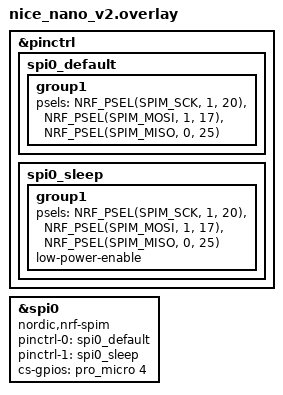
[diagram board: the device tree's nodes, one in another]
/*
 * Copyright (c) 2024 Curtis Bollinger
 *
 * SPDX-License-Identifier: MIT
 */

&pinctrl {
    spi0_default: spi0_default {
        group1 {
            psels = <NRF_PSEL(SPIM_SCK, 1, 20)>,  //SCL P3
                    <NRF_PSEL(SPIM_MOSI, 1, 17)>, //SDA P2
                    <NRF_PSEL(SPIM_MISO, 0, 25)>;
        };
    };
    spi0_sleep: spi0_sleep {
        group1 {
            psels = <NRF_PSEL(SPIM_SCK, 1, 20)>,
                    <NRF_PSEL(SPIM_MOSI, 1, 17)>,
                    <NRF_PSEL(SPIM_MISO, 0, 25)>;
            low-power-enable;
        };
    };
};

nice_view_spi: &spi0 {
    compatible = "nordic,nrf-spim";
    pinctrl-0 = <&spi0_default>;
    pinctrl-1 = <&spi0_sleep>;
    pinctrl-names = "default", "sleep";
    cs-gpios = <&pro_micro 4 GPIO_ACTIVE_HIGH>;  //CS P4
    status = "okay";
};
